# ATSAMRH71F20C register map
Vendor: Microchip Technology; Series: SAMRH71; File version: 0
CPU: CM7 r1p1, little endian, MPU, FPU, double-precision FPU, I-cache, D-cache, ITCM, DTCM, 3 interrupt priority bits, 75 interrupts
Registers are 32-bit, read-write, reset 0x0 unless marked. A register's access mark holds for its fields unless they carry their own. Offsets are from the block's base; [hi:lo] are bit positions; lines under a group give offsets from that group; {n}, {i} and the like mark numbered series.

## CHIPID — Chip Identifier
Base 0x40100000
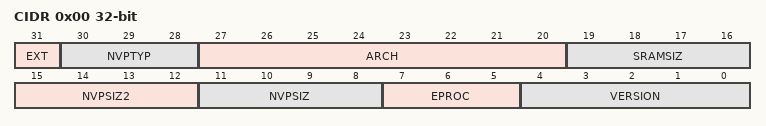
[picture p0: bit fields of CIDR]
0x00 CIDR ro — Chip ID Register
  [31] EXT — Extension Flag
  [30:28] NVPTYP — Nonvolatile Program Memory Type
    0=ROM; 1=ROMLESS (ROMless or on-chip Flash); 2=FLASH (Embedded Flash Memory); 3=ROM_FLASH (ROM and Embedded Flash Memory- NVPSIZ is ROM size- NVPSIZ2 is Flash size); 4=SRAM (SRAM emulating ROM)
  [27:20] ARCH — Architecture Identifier
    34=SAMRH71
  [19:16] SRAMSIZ — Internal SRAM Size
    0=_48K (48 Kbytes); 1=_192K (192 Kbytes); 2=_384K (384 Kbytes); 3=_6K (6 Kbytes); 4=_24K (24 Kbytes); 5=_4K (4 Kbytes); 6=_80K (80 Kbytes); 7=_160K (160 Kbytes); 8=_8K (8 Kbytes); 9=_16K (16 Kbytes); 10=_32K (32 Kbytes); 11=_64K (64 Kbytes); 12=_128K (128 Kbytes); 13=_256K (256 Kbytes); 14=_96K (96 Kbytes); 15=_512K (512 Kbytes)
  [15:12] NVPSIZ2 — Second Nonvolatile Program Memory Size
    0=NONE; 1=_8K (8 Kbytes); 2=_16K (16 Kbytes); 3=_32K (32 Kbytes); 5=_64K (64 Kbytes); 7=_128K (128 Kbytes); 9=_256K (256 Kbytes); 10=_512K (512 Kbytes); 12=_1024K (1024 Kbytes); 14=_2048K (2048 Kbytes)
  [11:8] NVPSIZ — Nonvolatile Program Memory Size
    0=NONE; 1=_8K (8 Kbytes); 2=_16K (16 Kbytes); 3=_32K (32 Kbytes); 5=_64K (64 Kbytes); 7=_128K (128 Kbytes); 8=_160K (160 Kbytes); 9=_256K (256 Kbytes); 10=_512K (512 Kbytes); 12=_1024K (1024 Kbytes); 14=_2048K (2048 Kbytes)
  [7:5] EPROC — Embedded Processor
    0=SAMx7 (Cortex-M7); 1=ARM946ES; 2=ARM7TDMI; 3=CM3 (Cortex-M3); 4=ARM920T; 5=ARM926EJS; 6=CA5 (Cortex-A5); 7=CM4 (Cortex-M4)
  [4:0] VERSION — Version of the Device
0x04 EXID ro — Chip ID Extension Register
  [31:0] EXID — Chip ID Extension
    1=PACKAGE_TYPE_256 (256-lead package)

## FLEXRAMECC
Base 0x40100600
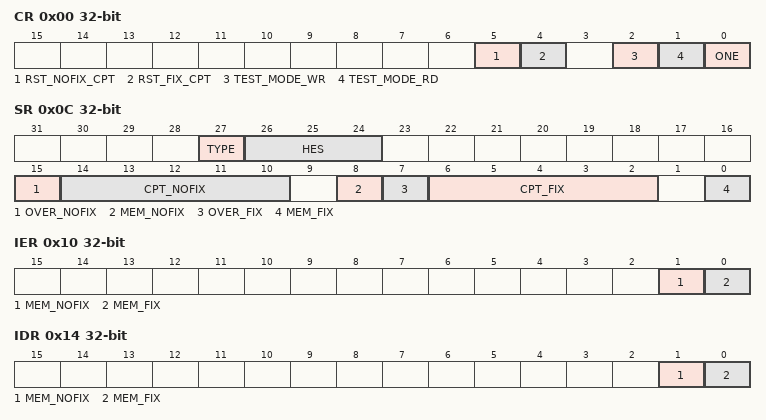
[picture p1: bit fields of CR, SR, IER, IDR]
0x00 CR — FLEXRAMECC Control Register
  [5] RST_NOFIX_CPT — reset the un-fixable error counter
  [4] RST_FIX_CPT — reset the fixable error counter
  [2] TEST_MODE_WR — test mode of ECC protection - write mode
  [1] TEST_MODE_RD — test mode of ECC protection - read mode
  [0] ONE — Shall be always write at '1'
0x04 TESTCB1 — FLEXRAMECC Test mode register 1
  [7:0] TCB1 — Test Check Bit
0x0C SR ro — FLEXRAMECC Status register
  [27] TYPE — write or read access
  [26:24] HES — Hardware Error Size
  [15] OVER_NOFIX — counter overflow
  [14:10] CPT_NOFIX — 5 bits counter
  [8] MEM_NOFIX — Un-fixable error status
  [7] OVER_FIX — counter overflow
  [6:2] CPT_FIX — 5 bits counter
  [0] MEM_FIX — Fixable error status
0x10 IER wo — FLEXRAMECC Interrupt Enable Register
  [1] MEM_NOFIX — Un-fixable error
  [0] MEM_FIX — Fixable error
0x14 IDR wo — FLEXRAMECC Interrupt Disable Register
  [1] MEM_NOFIX — un-fixable error
  [0] MEM_FIX — fixable error
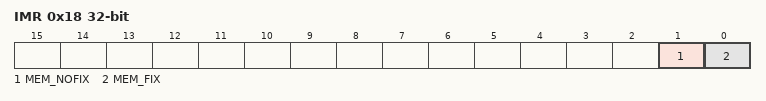
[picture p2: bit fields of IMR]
0x18 IMR ro — FLEXRAMECC Interrupt Mask Register
  [1] MEM_NOFIX — un-fixable error
  [0] MEM_FIX — fixable error
0x1C FAILAR ro — FLEXRAMECC Fail address register
  [31:0] ADDRESS — address of the error detected

## HSMC — Harden Static Memory Controller
Base 0x40081000
{0x0+0x10*i} HSMC_CS[{i}] (i=0..5) group
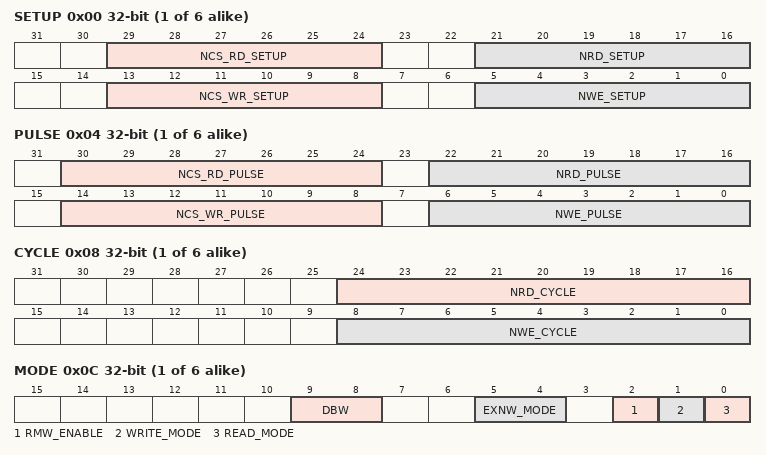
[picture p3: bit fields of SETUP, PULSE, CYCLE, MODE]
  0x00 SETUP — HSMC Setup Register
    [29:24] NCS_RD_SETUP — NCS Setup Length in READ Access
    [21:16] NRD_SETUP — NRD Setup Length
    [13:8] NCS_WR_SETUP — NCS Setup Length in WRITE Access
    [5:0] NWE_SETUP — NWE Setup Length
  0x04 PULSE — HSMC Pulse Register
    [30:24] NCS_RD_PULSE — NCS Pulse Length in READ Access
    [22:16] NRD_PULSE — NRD Pulse Length
    [14:8] NCS_WR_PULSE — NCS Pulse Length in WRITE Access
    [6:0] NWE_PULSE — NWE Pulse Length
  0x08 CYCLE — HSMC Cycle Register
    [24:16] NRD_CYCLE — Total Read Cycle Length
    [8:0] NWE_CYCLE — Total Write Cycle Length
  0x0C MODE — HSMC Mode Register
    [9:8] DBW — Data Bus Width
      0=_8_BIT (8-bit Data Bus); 1=_16_BIT (16-bit Data Bus); 2=_32_BIT (32-bit Data Bus)
    [5:4] EXNW_MODE — NWAIT Mode
      0=DISABLED (Disabled-The NWAIT input signal is ignored on the corresponding chip select.); 2=FROZEN (Frozen Mode-If asserted, the NWAIT signal freezes the current read or write cycle. After deassertion, the read/write cycle is resumed from the point where it was stopped.); 3=READY (Ready Mode-The NWAIT signal indicates the availability of the external device at the end of the pulse of the controlling read or write signal, to complete the access. If high, the access normally completes. If low, the access is extended until NWAIT returns high.)
    [2] RMW_ENABLE — Read-Modify Write enable
    [1] WRITE_MODE
    [0] READ_MODE
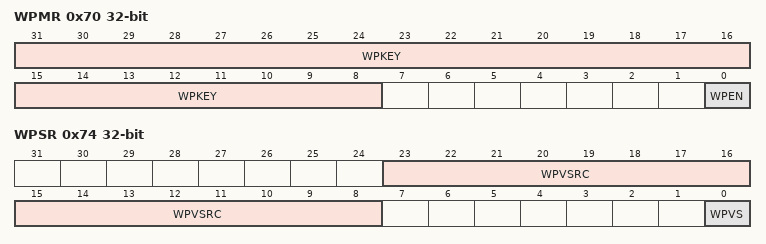
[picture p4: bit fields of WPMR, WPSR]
0x70 WPMR — HSMC Write Protection Mode Register
  [31:8] WPKEY — Write Protection Key
    0x534D43=PASSWD (Writing any other value in this field aborts the write operation of the WPEN bit. Always reads as 0.)
  [0] WPEN — Write Protect Enable
0x74 WPSR ro — HSMC Write Protection Status Register
  [23:8] WPVSRC — Write Protection Violation Source
  [0] WPVS — Write Protection Violation Status
